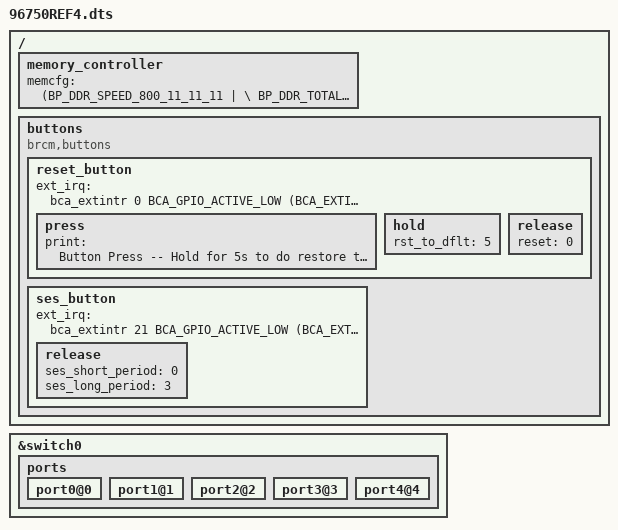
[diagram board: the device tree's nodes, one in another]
#include "63178.dtsi"

/ {
    memory_controller {
        memcfg = <(BP_DDR_SPEED_800_11_11_11 | \
                   BP_DDR_TOTAL_SIZE_512MB   | \
                   BP_DDR_DEVICE_WIDTH_16    | \
                   BP_DDR_TOTAL_WIDTH_16BIT  | \
                   BP_DDR_63178_DEFAULT)>;
    };

	buttons {
		compatible = "brcm,buttons";
		reset_button {
			ext_irq = <&bca_extintr 0 BCA_GPIO_ACTIVE_LOW (BCA_EXTINTR_TYPE_LOW_LEVEL | BCA_EXTINTR_TYPE_SENSE_EDGE)>;
			press {
				print = "Button Press -- Hold for 5s to do restore to default";
			};
			hold {
				rst_to_dflt = <5>;
			};
			release {
				reset = <0>;
			};	
		};
		ses_button {
			ext_irq = <&bca_extintr 21 BCA_GPIO_ACTIVE_LOW (BCA_EXTINTR_TYPE_LOW_LEVEL | BCA_EXTINTR_TYPE_SENSE_EDGE)>;
			release {
				ses_short_period = <0>;
				ses_long_period = <3>;
			};
		};
	};
};

&switch0 {
	ports {
		port0@0 {
			status = "okay";
		};

		port1@1 {
			status = "okay";
		};

		port2@2 {
			status = "okay";
		};

		port3@3 {
			status = "okay";
		};

		port4@4 {
			status = "okay";
		};
	};
};
